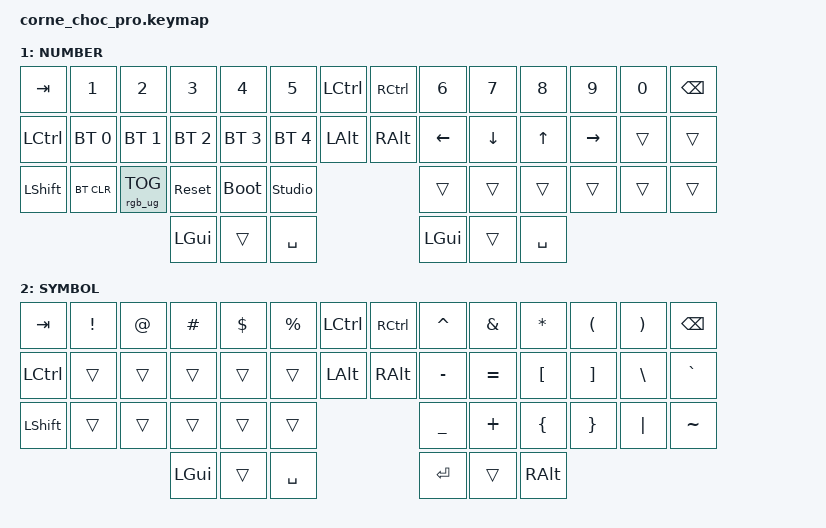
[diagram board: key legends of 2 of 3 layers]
/*
 * Copyright (c) 2020 The ZMK Contributors
 *
 * SPDX-License-Identifier: MIT
 */

#include <behaviors.dtsi>
#include <dt-bindings/zmk/keys.h>
#include <dt-bindings/zmk/bt.h>
#include <dt-bindings/zmk/rgb.h>

/ {
    chosen {
        zmk,physical-layout = &default_layout;
    };
};

/ {
    keymap {
        compatible = "zmk,keymap";

        default_layer {
            display-name = "CASEMEK";
            bindings = <                        
                &kp Q    &kp W    &kp F    &kp P    &kp B    &kp J    &kp L    &kp U    &kp Y    &kp SQT
                &kp A    &kp R    &kp S    &kp T    &kp G    &kp M    &kp N    &kp E    &kp I    &kp O
                &kp Z    &kp X    &kp C    &kp D    &kp V    &kp K    &kp H    &kp COMMA &kp DOT &kp SLASH

                &mt LSHFT ESC      &lt 1 TAB      &kp SPACE  &mt RGUI ENTER     &lt 2 BSPC     &kp RALT
            >;
        };

                lower_layer {
            display-name = "NUMBER";
            // -----------------------------------------------------------------------------------------
            // |  TAB |  1  |  2  |  3  |  4  |  5    |  LCTRL | RCTRL |  6  |  7  |  8  |  9  |  0  | BSPC |
            // | CTRL | BT1 | BT2 | BT3 | BT4 | BT5   |  LALT  | RALT  | LFT | DWN |  UP | RGT |     |      |
            // | SHFT | BTCR| RGB | RST | BOOT| Unlock|        |       |     |     |     |     |     |      |
            //                    | GUI |     | SPC   |        | ENT   |     | ALT |
            bindings = <
                &kp TAB   &kp N1       &kp N2          &kp N3       &kp N4       &kp N5       &kp LCTRL &kp RCTRL &kp N6   &kp N7   &kp N8 &kp N9    &kp N0 &kp BSPC
                &kp LCTRL &bt BT_SEL 0 &bt BT_SEL 1    &bt BT_SEL 2 &bt BT_SEL 3 &bt BT_SEL 4 &kp LALT  &kp RALT  &kp LEFT &kp DOWN &kp UP &kp RIGHT &trans &trans
                &kp LSHFT &bt BT_CLR   &rgb_ug RGB_TOG &sys_reset   &bootloader  &studio_unlock                   &trans   &trans   &trans &trans    &trans &trans
                                                       &kp LGUI     &trans       &kp SPACE                        &kp LGUI &trans   &kp SPACE
            >;
        };

        raise_layer {
            display-name = "SYMBOL";
            // -----------------------------------------------------------------------------------------
            // |  TAB |  !  |  @  |  #  |  $  |  %  | LCTRL | RCTRL |  ^  |  &  |  *  |  (  |  )  | BSPC |
            // | CTRL |     |     |     |     |     |  LALT | RALT  |  -  |  =  |  [  |  ]  |  \  |  `   |
            // | SHFT |     |     |     |     |     |               |  _  |  +  |  {  |  }  | "|" |  ~   |
            //                    | GUI |     | SPC |               | ENT |     | ALT |
            bindings = <
                &kp  TAB  &kp EXCL &kp AT &kp HASH &kp DLLR &kp PRCNT &kp LCTRL &kp RCTRL &kp CARET &kp AMPS &kp ASTRK &kp LPAR &kp RPAR &kp BSPC
                &kp LCTRL &trans   &trans &trans   &trans   &trans    &kp LALT  &kp RALT  &kp MINUS &kp EQUAL &kp LBKT &kp RBKT &kp BSLH &kp GRAVE
                &kp LSHFT &trans   &trans &trans   &trans   &trans                        &kp UNDER &kp PLUS  &kp LBRC &kp RBRC &kp PIPE &kp TILDE
                                          &kp LGUI &trans   &kp SPACE                     &kp RET   &trans    &kp RALT
            >;
        };
    };

    combos {
        compatible = "zmk,combos";

        combo_copy {
            timeout-ms = <50>;
            key-positions = <15 16>; // A + R
            bindings = <&kp LC(C)>;
        };

        combo_paste {
            timeout-ms = <50>;
            key-positions = <16 17>; // R + S
            bindings = <&kp LC(V)>;
        };

        combo_cut {
            timeout-ms = <50>;
            key-positions = <17 18>; // S + T
            bindings = <&kp LC(X)>;
        };

        combo_undo {
            timeout-ms = <50>;
            key-positions = <18 19>; // T + G
            bindings = <&kp LC(Z)>;
        };

        combo_redo {
            timeout-ms = <50>;
            key-positions = <19 20>; // G + M
            bindings = <&kp LC(Y)>;
        };
    };
};
